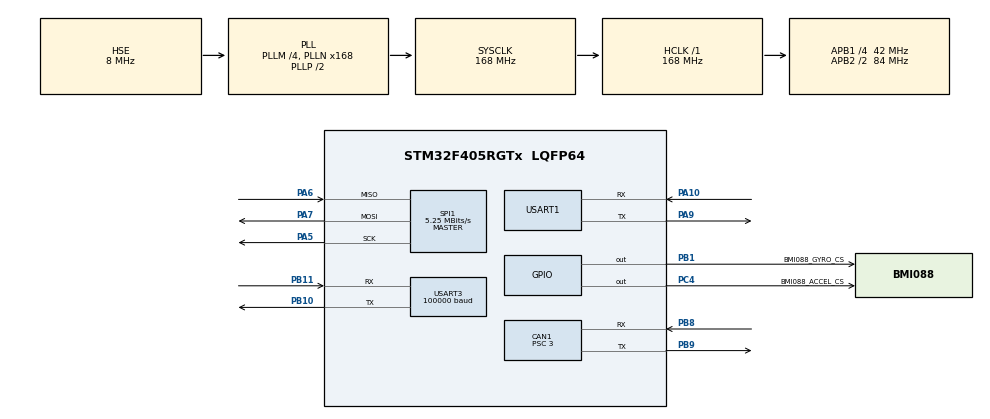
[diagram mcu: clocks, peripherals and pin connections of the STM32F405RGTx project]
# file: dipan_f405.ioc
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CAN1.BS1=CAN_BS1_11TQ
CAN1.BS2=CAN_BS2_2TQ
CAN1.CalculateBaudRate=1000000
CAN1.CalculateTimeBit=1000
CAN1.CalculateTimeQuantum=71.42857142857143
CAN1.Prescaler=3
Dma.Request0=USART1_RX
Dma.Request1=USART1_TX
Dma.Request2=USART3_RX
Dma.Request3=USART3_TX
Dma.USART1_RX.0.Direction=DMA_PERIPH_TO_MEMORY
Dma.USART1_RX.0.FIFOMode=DMA_FIFOMODE_DISABLE
Dma.USART1_RX.0.Instance=DMA2_Stream2
Dma.USART1_RX.0.MemDataAlignment=DMA_MDATAALIGN_BYTE
Dma.USART1_RX.0.MemInc=DMA_MINC_ENABLE
Dma.USART1_RX.0.Mode=DMA_NORMAL
Dma.USART1_RX.0.PeriphDataAlignment=DMA_PDATAALIGN_BYTE
Dma.USART1_RX.0.PeriphInc=DMA_PINC_DISABLE
Dma.USART1_RX.0.Priority=DMA_PRIORITY_LOW
Dma.USART1_TX.1.Direction=DMA_MEMORY_TO_PERIPH
Dma.USART1_TX.1.FIFOMode=DMA_FIFOMODE_DISABLE
Dma.USART1_TX.1.Instance=DMA2_Stream7
Dma.USART1_TX.1.MemDataAlignment=DMA_MDATAALIGN_BYTE
Dma.USART1_TX.1.MemInc=DMA_MINC_ENABLE
Dma.USART1_TX.1.Mode=DMA_NORMAL
Dma.USART1_TX.1.PeriphDataAlignment=DMA_PDATAALIGN_BYTE
Dma.USART1_TX.1.PeriphInc=DMA_PINC_DISABLE
Dma.USART1_TX.1.Priority=DMA_PRIORITY_LOW
Dma.USART3_RX.2.Direction=DMA_PERIPH_TO_MEMORY
Dma.USART3_RX.2.FIFOMode=DMA_FIFOMODE_DISABLE
Dma.USART3_RX.2.Instance=DMA1_Stream1
Dma.USART3_RX.2.MemDataAlignment=DMA_MDATAALIGN_BYTE
Dma.USART3_RX.2.MemInc=DMA_MINC_ENABLE
Dma.USART3_RX.2.Mode=DMA_NORMAL
Dma.USART3_RX.2.PeriphDataAlignment=DMA_PDATAALIGN_BYTE
Dma.USART3_RX.2.PeriphInc=DMA_PINC_DISABLE
Dma.USART3_RX.2.Priority=DMA_PRIORITY_LOW
Dma.USART3_TX.3.Direction=DMA_MEMORY_TO_PERIPH
Dma.USART3_TX.3.FIFOMode=DMA_FIFOMODE_DISABLE
Dma.USART3_TX.3.Instance=DMA1_Stream3
Dma.USART3_TX.3.MemDataAlignment=DMA_MDATAALIGN_BYTE
Dma.USART3_TX.3.MemInc=DMA_MINC_ENABLE
Dma.USART3_TX.3.Mode=DMA_NORMAL
Dma.USART3_TX.3.PeriphDataAlignment=DMA_PDATAALIGN_BYTE
Dma.USART3_TX.3.PeriphInc=DMA_PINC_DISABLE
Dma.USART3_TX.3.Priority=DMA_PRIORITY_LOW
FREERTOS.Tasks01=defaultTask,24,128,StartDefaultTask,Default,NULL,Dynamic,NULL,NULL;ctrlTask,24,128,ctrlStartTask,As weak,NULL,Dynamic,NULL,NULL;motorTask,32,128,motorStartTask,As weak,NULL,Dynamic,NULL,NULL
Mcu.Family=STM32F4
Mcu.Name=STM32F405RGTx
Mcu.Package=LQFP64
NVIC.CAN1_RX0_IRQn=true\:5\:0\:false\:false\:true\:true\:true\:true\:true
NVIC.CAN1_TX_IRQn=true\:5\:0\:false\:false\:true\:true\:true\:true\:true
NVIC.DMA1_Stream1_IRQn=true\:5\:0\:false\:false\:true\:true\:false\:true\:true
NVIC.DMA1_Stream3_IRQn=true\:5\:0\:false\:false\:true\:true\:false\:true\:true
NVIC.DMA2_Stream2_IRQn=true\:5\:0\:false\:false\:true\:true\:false\:true\:true
NVIC.DMA2_Stream7_IRQn=true\:5\:0\:false\:false\:true\:true\:false\:true\:true
NVIC.PriorityGroup=NVIC_PRIORITYGROUP_4
NVIC.SPI1_IRQn=true\:5\:0\:false\:false\:true\:true\:true\:true\:true
NVIC.TIM6_DAC_IRQn=true\:15\:0\:false\:false\:true\:false\:false\:true\:true
NVIC.TimeBase=TIM6_DAC_IRQn
NVIC.TimeBaseIP=TIM6
NVIC.USART1_IRQn=true\:5\:0\:false\:false\:true\:true\:true\:true\:true
NVIC.USART3_IRQn=true\:5\:0\:false\:false\:true\:true\:true\:true\:true
PA10.Mode=Asynchronous
PA10.Signal=USART1_RX
PA13.Mode=Serial_Wire
PA13.Signal=SYS_JTMS-SWDIO
PA14.Mode=Serial_Wire
PA14.Signal=SYS_JTCK-SWCLK
PA5.Mode=Full_Duplex_Master
PA5.Signal=SPI1_SCK
PA6.Mode=Full_Duplex_Master
PA6.Signal=SPI1_MISO
PA7.Mode=Full_Duplex_Master
PA7.Signal=SPI1_MOSI
PA9.Mode=Asynchronous
PA9.Signal=USART1_TX
PB1.GPIO_Label=BMI088_GYRO_CS
PB1.PinState=GPIO_PIN_SET
PB1.Signal=GPIO_Output
PB10.Mode=Asynchronous
PB10.Signal=USART3_TX
PB11.Mode=Asynchronous
PB11.Signal=USART3_RX
PB8.Mode=CAN_Activate
PB8.Signal=CAN1_RX
PB9.Mode=CAN_Activate
PB9.Signal=CAN1_TX
PC4.GPIO_Label=BMI088_ACCEL_CS
PC4.PinState=GPIO_PIN_SET
PC4.Signal=GPIO_Output
PH0-OSC_IN.Mode=HSE-External-Oscillator
PH0-OSC_IN.Signal=RCC_OSC_IN
PH1-OSC_OUT.Mode=HSE-External-Oscillator
PH1-OSC_OUT.Signal=RCC_OSC_OUT
ProjectManager.HeapSize=0x200
ProjectManager.StackSize=0x400
ProjectManager.TargetToolchain=CMake
RCC.48MHZClocksFreq_Value=84000000
RCC.AHBFreq_Value=168000000
RCC.APB1CLKDivider=RCC_HCLK_DIV4
RCC.APB1Freq_Value=42000000
RCC.APB1TimFreq_Value=84000000
RCC.APB2CLKDivider=RCC_HCLK_DIV2
RCC.APB2Freq_Value=84000000
RCC.APB2TimFreq_Value=168000000
RCC.CortexFreq_Value=168000000
RCC.HCLKFreq_Value=168000000
RCC.HSE_VALUE=8000000
RCC.HSI_VALUE=16000000
RCC.LSE_VALUE=32768
RCC.PLLM=4
RCC.PLLN=168
RCC.PLLSourceVirtual=RCC_PLLSOURCE_HSE
RCC.SYSCLKFreq_VALUE=168000000
RCC.SYSCLKSource=RCC_SYSCLKSOURCE_PLLCLK
RCC.VCOOutputFreq_Value=336000000
SPI1.BaudRatePrescaler=SPI_BAUDRATEPRESCALER_16
SPI1.CalculateBaudRate=5.25 MBits/s
SPI1.Direction=SPI_DIRECTION_2LINES
SPI1.Mode=SPI_MODE_MASTER
SPI1.VirtualType=VM_MASTER
USART1.VirtualMode=VM_ASYNC
USART3.BaudRate=100000
USART3.Parity=PARITY_EVEN
USART3.StopBits=STOPBITS_2
USART3.VirtualMode=VM_ASYNC
USART3.WordLength=WORDLENGTH_9B
VP_FREERTOS_VS_CMSIS_V2.Mode=CMSIS_V2
VP_SYS_VS_tim6.Mode=TIM6
board=custom

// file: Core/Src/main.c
/* USER CODE BEGIN Header */
/**
  ******************************************************************************
  * @file           : main.c
  * @brief          : Main program body
  ******************************************************************************
  * @attention
  *
  * Copyright (c) 2026 STMicroelectronics.
  * All rights reserved.
  *
  * This software is licensed under terms that can be found in the LICENSE file
  * in the root directory of this software component.
  * If no LICENSE file comes with this software, it is provided AS-IS.
  *
  ******************************************************************************
  */
/* USER CODE END Header */
#include "main.h"
#include "cmsis_os.h"

/* USER CODE BEGIN Includes */
#include "app_task.h"

/* USER CODE END Includes */

CAN_HandleTypeDef hcan1;

SPI_HandleTypeDef hspi1;

UART_HandleTypeDef huart1;
UART_HandleTypeDef huart3;
DMA_HandleTypeDef hdma_usart1_rx;
DMA_HandleTypeDef hdma_usart1_tx;
DMA_HandleTypeDef hdma_usart3_rx;
DMA_HandleTypeDef hdma_usart3_tx;

/* Definitions for defaultTask */
osThreadId_t defaultTaskHandle;
const osThreadAttr_t defaultTask_attributes = {
  .name = "defaultTask",
  .stack_size = 128 * 4,
  .priority = (osPriority_t) osPriorityNormal,
};
/* Definitions for ctrlTask */
osThreadId_t ctrlTaskHandle;
const osThreadAttr_t ctrlTask_attributes = {
  .name = "ctrlTask",
  .stack_size = 128 * 4,
  .priority = (osPriority_t) osPriorityNormal,
};
/* Definitions for motorTask */
osThreadId_t motorTaskHandle;
const osThreadAttr_t motorTask_attributes = {
  .name = "motorTask",
  .stack_size = 128 * 4,
  .priority = (osPriority_t) osPriorityAboveNormal,
};

void SystemClock_Config(void);
static void MX_GPIO_Init(void);
static void MX_DMA_Init(void);
static void MX_CAN1_Init(void);
static void MX_USART1_UART_Init(void);
static void MX_USART3_UART_Init(void);
static void MX_SPI1_Init(void);
void StartDefaultTask(void *argument);
void ctrlStartTask(void *argument);
void motorStartTask(void *argument);

int main(void)
{

  /* MCU Configuration--------------------------------------------------------*/

  /* Reset of all peripherals, Initializes the Flash interface and the Systick. */
  HAL_Init();

  /* Configure the system clock */
  SystemClock_Config();

  /* Initialize all configured peripherals */
  MX_GPIO_Init();
  MX_DMA_Init();
  MX_CAN1_Init();
  MX_USART1_UART_Init();
  MX_USART3_UART_Init();
  MX_SPI1_Init();

  /* Init scheduler */
  osKernelInitialize();

  /* Create the thread(s) */
  /* creation of defaultTask */
  defaultTaskHandle = osThreadNew(StartDefaultTask, NULL, &defaultTask_attributes);

  /* creation of ctrlTask */
  ctrlTaskHandle = osThreadNew(ctrlStartTask, NULL, &ctrlTask_attributes);

  /* creation of motorTask */
  motorTaskHandle = osThreadNew(motorStartTask, NULL, &motorTask_attributes);

  /* Start scheduler */
  osKernelStart();

  /* We should never get here as control is now taken by the scheduler */

  /* Infinite loop */
  while (1)
  {

  }
}

void SystemClock_Config(void)
{
  RCC_OscInitTypeDef RCC_OscInitStruct = {0};
  RCC_ClkInitTypeDef RCC_ClkInitStruct = {0};

  /** Configure the main internal regulator output voltage
  */
  __HAL_RCC_PWR_CLK_ENABLE();
  __HAL_PWR_VOLTAGESCALING_CONFIG(PWR_REGULATOR_VOLTAGE_SCALE1);

  /** Initializes the RCC Oscillators according to the specified parameters
  * in the RCC_OscInitTypeDef structure.
  */
  RCC_OscInitStruct.OscillatorType = RCC_OSCILLATORTYPE_HSE;
  RCC_OscInitStruct.HSEState = RCC_HSE_ON;
  RCC_OscInitStruct.PLL.PLLState = RCC_PLL_ON;
  RCC_OscInitStruct.PLL.PLLSource = RCC_PLLSOURCE_HSE;
  RCC_OscInitStruct.PLL.PLLM = 4;
  RCC_OscInitStruct.PLL.PLLN = 168;
  RCC_OscInitStruct.PLL.PLLP = RCC_PLLP_DIV2;
  RCC_OscInitStruct.PLL.PLLQ = 4;
  if (HAL_RCC_OscConfig(&RCC_OscInitStruct) != HAL_OK)
  {
    Error_Handler();
  }

  /** Initializes the CPU, AHB and APB buses clocks
  */
  RCC_ClkInitStruct.ClockType = RCC_CLOCKTYPE_HCLK|RCC_CLOCKTYPE_SYSCLK
                              |RCC_CLOCKTYPE_PCLK1|RCC_CLOCKTYPE_PCLK2;
  RCC_ClkInitStruct.SYSCLKSource = RCC_SYSCLKSOURCE_PLLCLK;
  RCC_ClkInitStruct.AHBCLKDivider = RCC_SYSCLK_DIV1;
  RCC_ClkInitStruct.APB1CLKDivider = RCC_HCLK_DIV4;
  RCC_ClkInitStruct.APB2CLKDivider = RCC_HCLK_DIV2;

  if (HAL_RCC_ClockConfig(&RCC_ClkInitStruct, FLASH_LATENCY_5) != HAL_OK)
  {
    Error_Handler();
  }
}

static void MX_CAN1_Init(void)
{

  hcan1.Instance = CAN1;
  hcan1.Init.Prescaler = 3;
  hcan1.Init.Mode = CAN_MODE_NORMAL;
  hcan1.Init.SyncJumpWidth = CAN_SJW_1TQ;
  hcan1.Init.TimeSeg1 = CAN_BS1_11TQ;
  hcan1.Init.TimeSeg2 = CAN_BS2_2TQ;
  hcan1.Init.TimeTriggeredMode = DISABLE;
  hcan1.Init.AutoBusOff = DISABLE;
  hcan1.Init.AutoWakeUp = DISABLE;
  hcan1.Init.AutoRetransmission = DISABLE;
  hcan1.Init.ReceiveFifoLocked = DISABLE;
  hcan1.Init.TransmitFifoPriority = DISABLE;
  if (HAL_CAN_Init(&hcan1) != HAL_OK)
  {
    Error_Handler();
  }

}

static void MX_SPI1_Init(void)
{

  /* SPI1 parameter configuration*/
  hspi1.Instance = SPI1;
  hspi1.Init.Mode = SPI_MODE_MASTER;
  hspi1.Init.Direction = SPI_DIRECTION_2LINES;
  hspi1.Init.DataSize = SPI_DATASIZE_8BIT;
  hspi1.Init.CLKPolarity = SPI_POLARITY_LOW;
  hspi1.Init.CLKPhase = SPI_PHASE_1EDGE;
  hspi1.Init.NSS = SPI_NSS_SOFT;
  hspi1.Init.BaudRatePrescaler = SPI_BAUDRATEPRESCALER_16;
  hspi1.Init.FirstBit = SPI_FIRSTBIT_MSB;
  hspi1.Init.TIMode = SPI_TIMODE_DISABLE;
  hspi1.Init.CRCCalculation = SPI_CRCCALCULATION_DISABLE;
  hspi1.Init.CRCPolynomial = 10;
  if (HAL_SPI_Init(&hspi1) != HAL_OK)
  {
    Error_Handler();
  }

}

static void MX_USART1_UART_Init(void)
{

  huart1.Instance = USART1;
  huart1.Init.BaudRate = 115200;
  huart1.Init.WordLength = UART_WORDLENGTH_8B;
  huart1.Init.StopBits = UART_STOPBITS_1;
  huart1.Init.Parity = UART_PARITY_NONE;
  huart1.Init.Mode = UART_MODE_TX_RX;
  huart1.Init.HwFlowCtl = UART_HWCONTROL_NONE;
  huart1.Init.OverSampling = UART_OVERSAMPLING_16;
  if (HAL_UART_Init(&huart1) != HAL_OK)
  {
    Error_Handler();
  }

}

static void MX_USART3_UART_Init(void)
{

  huart3.Instance = USART3;
  huart3.Init.BaudRate = 100000;
  huart3.Init.WordLength = UART_WORDLENGTH_9B;
  huart3.Init.StopBits = UART_STOPBITS_2;
  huart3.Init.Parity = UART_PARITY_EVEN;
  huart3.Init.Mode = UART_MODE_TX_RX;
  huart3.Init.HwFlowCtl = UART_HWCONTROL_NONE;
  huart3.Init.OverSampling = UART_OVERSAMPLING_16;
  if (HAL_UART_Init(&huart3) != HAL_OK)
  {
    Error_Handler();
  }

}

static void MX_DMA_Init(void)
{

  /* DMA controller clock enable */
  __HAL_RCC_DMA2_CLK_ENABLE();
  __HAL_RCC_DMA1_CLK_ENABLE();

  /* DMA interrupt init */
  /* DMA1_Stream1_IRQn interrupt configuration */
  HAL_NVIC_SetPriority(DMA1_Stream1_IRQn, 5, 0);
  HAL_NVIC_EnableIRQ(DMA1_Stream1_IRQn);
  /* DMA1_Stream3_IRQn interrupt configuration */
  HAL_NVIC_SetPriority(DMA1_Stream3_IRQn, 5, 0);
  HAL_NVIC_EnableIRQ(DMA1_Stream3_IRQn);
  /* DMA2_Stream2_IRQn interrupt configuration */
  HAL_NVIC_SetPriority(DMA2_Stream2_IRQn, 5, 0);
  HAL_NVIC_EnableIRQ(DMA2_Stream2_IRQn);
  /* DMA2_Stream7_IRQn interrupt configuration */
  HAL_NVIC_SetPriority(DMA2_Stream7_IRQn, 5, 0);
  HAL_NVIC_EnableIRQ(DMA2_Stream7_IRQn);

}

static void MX_GPIO_Init(void)
{
  GPIO_InitTypeDef GPIO_InitStruct = {0};

  /* GPIO Ports Clock Enable */
  __HAL_RCC_GPIOH_CLK_ENABLE();
  __HAL_RCC_GPIOA_CLK_ENABLE();
  __HAL_RCC_GPIOC_CLK_ENABLE();
  __HAL_RCC_GPIOB_CLK_ENABLE();

  /*Configure GPIO pin Output Level */
  HAL_GPIO_WritePin(BMI088_ACCEL_CS_GPIO_Port, BMI088_ACCEL_CS_Pin, GPIO_PIN_SET);

  /*Configure GPIO pin Output Level */
  HAL_GPIO_WritePin(BMI088_GYRO_CS_GPIO_Port, BMI088_GYRO_CS_Pin, GPIO_PIN_SET);

  /*Configure GPIO pin : BMI088_ACCEL_CS_Pin */
  GPIO_InitStruct.Pin = BMI088_ACCEL_CS_Pin;
  GPIO_InitStruct.Mode = GPIO_MODE_OUTPUT_PP;
  GPIO_InitStruct.Pull = GPIO_NOPULL;
  GPIO_InitStruct.Speed = GPIO_SPEED_FREQ_LOW;
  HAL_GPIO_Init(BMI088_ACCEL_CS_GPIO_Port, &GPIO_InitStruct);

  /*Configure GPIO pin : BMI088_GYRO_CS_Pin */
  GPIO_InitStruct.Pin = BMI088_GYRO_CS_Pin;
  GPIO_InitStruct.Mode = GPIO_MODE_OUTPUT_PP;
  GPIO_InitStruct.Pull = GPIO_NOPULL;
  GPIO_InitStruct.Speed = GPIO_SPEED_FREQ_LOW;
  HAL_GPIO_Init(BMI088_GYRO_CS_GPIO_Port, &GPIO_InitStruct);

}

void StartDefaultTask(void *argument)
{
  for(;;)
  {
    osDelay(1);
  }
}

__weak void ctrlStartTask(void *argument)
{
  for(;;)
  {
    osDelay(1);
  }
}

__weak void motorStartTask(void *argument)
{
  for(;;)
  {
    osDelay(1);
  }
}

void HAL_TIM_PeriodElapsedCallback(TIM_HandleTypeDef *htim)
{
  if (htim->Instance == TIM6)
  {
    HAL_IncTick();
  }
}

void Error_Handler(void)
{
  __disable_irq();
  while (1)
  {
  }
}
